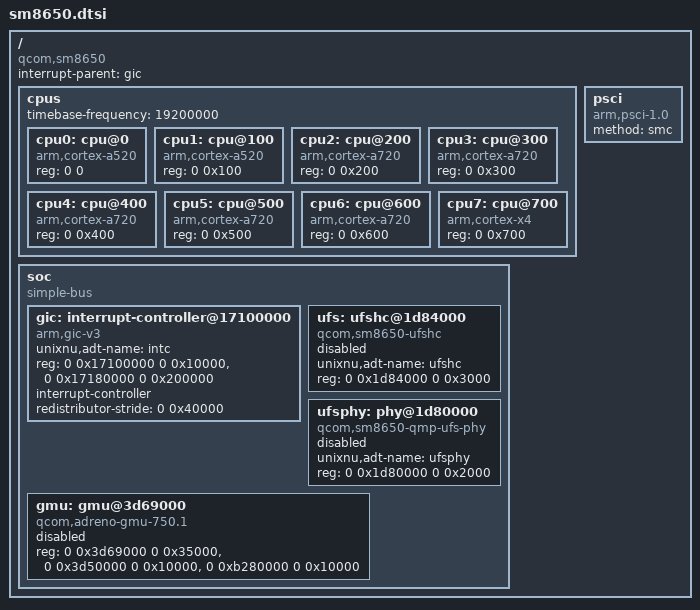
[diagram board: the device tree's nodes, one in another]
// SPDX-License-Identifier: BSD-2-Clause-Patent
// Qualcomm SM8650 (pineapple / kirby) — 拓扑取自本机实测
//   cpu0-1  A520  2.2656 GHz  capacity 379
//   cpu2-4  A720  3.1488 GHz  capacity 923
//   cpu5-6  A720  2.9568 GHz  capacity 867
//   cpu7    X4    3.3024 GHz  capacity 1024
/ {
    compatible = "qcom,sm8650";
    #address-cells = <2>;
    #size-cells = <2>;
    interrupt-parent = <&gic>;

    cpus {
        #address-cells = <2>;
        #size-cells = <0>;
        timebase-frequency = <19200000>;

        cpu0: cpu@0 { device_type = "cpu"; compatible = "arm,cortex-a520"; reg = <0 0>; };
        cpu1: cpu@100 { device_type = "cpu"; compatible = "arm,cortex-a520"; reg = <0 0x100>; };
        cpu2: cpu@200 { device_type = "cpu"; compatible = "arm,cortex-a720"; reg = <0 0x200>; };
        cpu3: cpu@300 { device_type = "cpu"; compatible = "arm,cortex-a720"; reg = <0 0x300>; };
        cpu4: cpu@400 { device_type = "cpu"; compatible = "arm,cortex-a720"; reg = <0 0x400>; };
        cpu5: cpu@500 { device_type = "cpu"; compatible = "arm,cortex-a720"; reg = <0 0x500>; };
        cpu6: cpu@600 { device_type = "cpu"; compatible = "arm,cortex-a720"; reg = <0 0x600>; };
        cpu7: cpu@700 { device_type = "cpu"; compatible = "arm,cortex-x4"; reg = <0 0x700>; };
    };

    psci { compatible = "arm,psci-1.0"; method = "smc"; };

    soc {
        compatible = "simple-bus";
        #address-cells = <2>;
        #size-cells = <2>;
        ranges;

        gic: interrupt-controller@17100000 {
            compatible = "arm,gic-v3";
            unixnu,adt-name = "intc";
            reg = <0 0x17100000 0 0x10000>, <0 0x17180000 0 0x200000>;
            #interrupt-cells = <4>;
            #address-cells = <0>;
            interrupt-controller;
            redistributor-stride = <0 0x40000>;
        };

        ufs: ufshc@1d84000 {
            compatible = "qcom,sm8650-ufshc";
            unixnu,adt-name = "ufshc";
            reg = <0 0x1d84000 0 0x3000>;
            status = "disabled";
        };

        ufsphy: phy@1d80000 {
            compatible = "qcom,sm8650-qmp-ufs-phy";
            unixnu,adt-name = "ufsphy";
            reg = <0 0x1d80000 0 0x2000>;
            status = "disabled";
        };

        // GMU 地址与 SM8550 不同：本机实测 qcom,gmu@3d69000
        gmu: gmu@3d69000 {
            compatible = "qcom,adreno-gmu-750.1", "qcom,adreno-gmu";
            reg = <0 0x3d69000 0 0x35000>, <0 0x3d50000 0 0x10000>, <0 0xb280000 0 0x10000>;
            reg-names = "gmu", "rscc", "gmu_pdc";
            status = "disabled";
        };
    };
};
